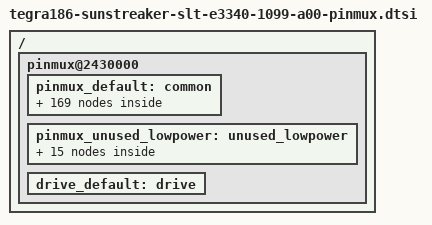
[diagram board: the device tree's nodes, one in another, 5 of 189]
/*
 * Copyright (c) 2015, NVIDIA CORPORATION.  All rights reserved.
 *
 * This program is free software; you can redistribute it and/or modify
 * it under the terms of the GNU General Public License as published by
 * the Free Software Foundation; either version 2 of the License, or
 * (at your option) any later version.
 *
 * This program is distributed in the hope that it will be useful, but WITHOUT
 * ANY WARRANTY; without even the implied warranty of MERCHANTABILITY or
 * FITNESS FOR A PARTICULAR PURPOSE.  See the GNU General Public License for
 * more details.
 */

#include <dt-bindings/pinctrl/pinctrl-tegra.h>

/ {
	pinmux@2430000 {
		pinctrl-names = "default", "drive", "unused";
		pinctrl-0 = <&pinmux_default>;
		pinctrl-1 = <&drive_default>;
		pinctrl-2 = <&pinmux_unused_lowpower>;

		pinmux_default: common {
			/* SFIO Pin Configuration */
			uart4_tx_pb0 {
				nvidia,pins = "uart4_tx_pb0";
				nvidia,function = "uartd";
				nvidia,pull = <TEGRA_PIN_PULL_NONE>;
				nvidia,tristate = <TEGRA_PIN_DISABLE>;
				nvidia,enable-input = <TEGRA_PIN_DISABLE>;
			};

			uart4_rx_pb1 {
				nvidia,pins = "uart4_rx_pb1";
				nvidia,function = "uartd";
				nvidia,pull = <TEGRA_PIN_PULL_UP>;
				nvidia,tristate = <TEGRA_PIN_DISABLE>;
				nvidia,enable-input = <TEGRA_PIN_ENABLE>;
			};

			uart4_rts_pb2 {
				nvidia,pins = "uart4_rts_pb2";
				nvidia,function = "uartd";
				nvidia,pull = <TEGRA_PIN_PULL_NONE>;
				nvidia,tristate = <TEGRA_PIN_DISABLE>;
				nvidia,enable-input = <TEGRA_PIN_DISABLE>;
			};

			uart4_cts_pb3 {
				nvidia,pins = "uart4_cts_pb3";
				nvidia,function = "uartd";
				nvidia,pull = <TEGRA_PIN_PULL_UP>;
				nvidia,tristate = <TEGRA_PIN_DISABLE>;
				nvidia,enable-input = <TEGRA_PIN_ENABLE>;
			};

			dap2_sclk_pc1 {
				nvidia,pins = "dap2_sclk_pc1";
				nvidia,function = "i2s2";
				nvidia,pull = <TEGRA_PIN_PULL_NONE>;
				nvidia,tristate = <TEGRA_PIN_DISABLE>;
				nvidia,enable-input = <TEGRA_PIN_ENABLE>;
			};

			dap2_dout_pc2 {
				nvidia,pins = "dap2_dout_pc2";
				nvidia,function = "i2s2";
				nvidia,pull = <TEGRA_PIN_PULL_NONE>;
				nvidia,tristate = <TEGRA_PIN_DISABLE>;
				nvidia,enable-input = <TEGRA_PIN_ENABLE>;
			};

			dap2_din_pc3 {
				nvidia,pins = "dap2_din_pc3";
				nvidia,function = "i2s2";
				nvidia,pull = <TEGRA_PIN_PULL_NONE>;
				nvidia,tristate = <TEGRA_PIN_DISABLE>;
				nvidia,enable-input = <TEGRA_PIN_ENABLE>;
			};

			dap2_fs_pc4 {
				nvidia,pins = "dap2_fs_pc4";
				nvidia,function = "i2s2";
				nvidia,pull = <TEGRA_PIN_PULL_NONE>;
				nvidia,tristate = <TEGRA_PIN_DISABLE>;
				nvidia,enable-input = <TEGRA_PIN_ENABLE>;
			};

			gen1_i2c_scl_pc5 {
				nvidia,pins = "gen1_i2c_scl_pc5";
				nvidia,function = "i2c1";
				nvidia,pull = <TEGRA_PIN_PULL_NONE>;
				nvidia,tristate = <TEGRA_PIN_DISABLE>;
				nvidia,enable-input = <TEGRA_PIN_ENABLE>;
				nvidia,io-high-voltage = <TEGRA_PIN_DISABLE>;
			};

			gen1_i2c_sda_pc6 {
				nvidia,pins = "gen1_i2c_sda_pc6";
				nvidia,function = "i2c1";
				nvidia,pull = <TEGRA_PIN_PULL_NONE>;
				nvidia,tristate = <TEGRA_PIN_DISABLE>;
				nvidia,enable-input = <TEGRA_PIN_ENABLE>;
				nvidia,io-high-voltage = <TEGRA_PIN_DISABLE>;
			};

			dap1_sclk_pj0 {
				nvidia,pins = "dap1_sclk_pj0";
				nvidia,function = "i2s1";
				nvidia,pull = <TEGRA_PIN_PULL_NONE>;
				nvidia,tristate = <TEGRA_PIN_DISABLE>;
				nvidia,enable-input = <TEGRA_PIN_ENABLE>;
			};

			dap1_dout_pj1 {
				nvidia,pins = "dap1_dout_pj1";
				nvidia,function = "i2s1";
				nvidia,pull = <TEGRA_PIN_PULL_NONE>;
				nvidia,tristate = <TEGRA_PIN_DISABLE>;
				nvidia,enable-input = <TEGRA_PIN_ENABLE>;
			};

			dap1_din_pj2 {
				nvidia,pins = "dap1_din_pj2";
				nvidia,function = "i2s1";
				nvidia,pull = <TEGRA_PIN_PULL_NONE>;
				nvidia,tristate = <TEGRA_PIN_DISABLE>;
				nvidia,enable-input = <TEGRA_PIN_ENABLE>;
			};

			dap1_fs_pj3 {
				nvidia,pins = "dap1_fs_pj3";
				nvidia,function = "i2s1";
				nvidia,pull = <TEGRA_PIN_PULL_NONE>;
				nvidia,tristate = <TEGRA_PIN_DISABLE>;
				nvidia,enable-input = <TEGRA_PIN_ENABLE>;
			};

			aud_mclk_pj4 {
				nvidia,pins = "aud_mclk_pj4";
				nvidia,function = "aud";
				nvidia,pull = <TEGRA_PIN_PULL_NONE>;
				nvidia,tristate = <TEGRA_PIN_DISABLE>;
				nvidia,enable-input = <TEGRA_PIN_DISABLE>;
			};

			dmic1_clk_pm1 {
				nvidia,pins = "dmic1_clk_pm1";
				nvidia,function = "i2s3";
				nvidia,pull = <TEGRA_PIN_PULL_NONE>;
				nvidia,tristate = <TEGRA_PIN_DISABLE>;
				nvidia,enable-input = <TEGRA_PIN_ENABLE>;
			};

			dmic1_dat_pm0 {
				nvidia,pins = "dmic1_dat_pm0";
				nvidia,function = "i2s3";
				nvidia,pull = <TEGRA_PIN_PULL_NONE>;
				nvidia,tristate = <TEGRA_PIN_DISABLE>;
				nvidia,enable-input = <TEGRA_PIN_ENABLE>;
			};

			dmic2_clk_pm3 {
				nvidia,pins = "dmic2_clk_pm3";
				nvidia,function = "i2s3";
				nvidia,pull = <TEGRA_PIN_PULL_NONE>;
				nvidia,tristate = <TEGRA_PIN_DISABLE>;
				nvidia,enable-input = <TEGRA_PIN_ENABLE>;
			};

			dmic2_dat_pm2 {
				nvidia,pins = "dmic2_dat_pm2";
				nvidia,function = "i2s3";
				nvidia,pull = <TEGRA_PIN_PULL_NONE>;
				nvidia,tristate = <TEGRA_PIN_DISABLE>;
				nvidia,enable-input = <TEGRA_PIN_ENABLE>;
			};

			dap4_sclk_pcc0 {
				nvidia,pins = "dap4_sclk_pcc0";
				nvidia,function = "i2s4";
				nvidia,pull = <TEGRA_PIN_PULL_NONE>;
				nvidia,tristate = <TEGRA_PIN_DISABLE>;
				nvidia,enable-input = <TEGRA_PIN_ENABLE>;
			};

			dap4_dout_pcc1 {
				nvidia,pins = "dap4_dout_pcc1";
				nvidia,function = "i2s4";
				nvidia,pull = <TEGRA_PIN_PULL_NONE>;
				nvidia,tristate = <TEGRA_PIN_DISABLE>;
				nvidia,enable-input = <TEGRA_PIN_ENABLE>;
			};

			dap4_din_pcc2 {
				nvidia,pins = "dap4_din_pcc2";
				nvidia,function = "i2s4";
				nvidia,pull = <TEGRA_PIN_PULL_NONE>;
				nvidia,tristate = <TEGRA_PIN_DISABLE>;
				nvidia,enable-input = <TEGRA_PIN_ENABLE>;
			};

			dap4_fs_pcc3 {
				nvidia,pins = "dap4_fs_pcc3";
				nvidia,function = "i2s4";
				nvidia,pull = <TEGRA_PIN_PULL_NONE>;
				nvidia,tristate = <TEGRA_PIN_DISABLE>;
				nvidia,enable-input = <TEGRA_PIN_ENABLE>;
			};

			pq0 {
				nvidia,pins = "pq0";
				nvidia,function = "i2s6";
				nvidia,pull = <TEGRA_PIN_PULL_NONE>;
				nvidia,tristate = <TEGRA_PIN_DISABLE>;
				nvidia,enable-input = <TEGRA_PIN_ENABLE>;
			};

			pq1 {
				nvidia,pins = "pq1";
				nvidia,function = "i2s6";
				nvidia,pull = <TEGRA_PIN_PULL_NONE>;
				nvidia,tristate = <TEGRA_PIN_DISABLE>;
				nvidia,enable-input = <TEGRA_PIN_ENABLE>;
			};

			pq2 {
				nvidia,pins = "pq2";
				nvidia,function = "i2s6";
				nvidia,pull = <TEGRA_PIN_PULL_NONE>;
				nvidia,tristate = <TEGRA_PIN_DISABLE>;
				nvidia,enable-input = <TEGRA_PIN_ENABLE>;
			};

			pq3 {
				nvidia,pins = "pq3";
				nvidia,function = "i2s6";
				nvidia,pull = <TEGRA_PIN_PULL_NONE>;
				nvidia,tristate = <TEGRA_PIN_DISABLE>;
				nvidia,enable-input = <TEGRA_PIN_ENABLE>;
			};

			gpio_cam2_pn1 {
				nvidia,pins = "gpio_cam2_pn1";
				nvidia,function = "extperiph3";
				nvidia,pull = <TEGRA_PIN_PULL_NONE>;
				nvidia,tristate = <TEGRA_PIN_DISABLE>;
				nvidia,enable-input = <TEGRA_PIN_DISABLE>;
			};

			gpio_cam4_pn3 {
				nvidia,pins = "gpio_cam4_pn3";
				nvidia,function = "spi4";
				nvidia,pull = <TEGRA_PIN_PULL_NONE>;
				nvidia,tristate = <TEGRA_PIN_DISABLE>;
				nvidia,enable-input = <TEGRA_PIN_DISABLE>;
			};

			gpio_cam5_pn4 {
				nvidia,pins = "gpio_cam5_pn4";
				nvidia,function = "spi4";
				nvidia,pull = <TEGRA_PIN_PULL_NONE>;
				nvidia,tristate = <TEGRA_PIN_DISABLE>;
				nvidia,enable-input = <TEGRA_PIN_ENABLE>;
			};

			gpio_cam6_pn5 {
				nvidia,pins = "gpio_cam6_pn5";
				nvidia,function = "spi4";
				nvidia,pull = <TEGRA_PIN_PULL_NONE>;
				nvidia,tristate = <TEGRA_PIN_DISABLE>;
				nvidia,enable-input = <TEGRA_PIN_DISABLE>;
			};

			gpio_cam7_pn6 {
				nvidia,pins = "gpio_cam7_pn6";
				nvidia,function = "spi4";
				nvidia,pull = <TEGRA_PIN_PULL_NONE>;
				nvidia,tristate = <TEGRA_PIN_DISABLE>;
				nvidia,enable-input = <TEGRA_PIN_DISABLE>;
			};

			cam_i2c_scl_po2 {
				nvidia,pins = "cam_i2c_scl_po2";
				nvidia,function = "i2c3";
				nvidia,pull = <TEGRA_PIN_PULL_NONE>;
				nvidia,tristate = <TEGRA_PIN_DISABLE>;
				nvidia,enable-input = <TEGRA_PIN_ENABLE>;
				nvidia,io-high-voltage = <TEGRA_PIN_DISABLE>;
			};

			cam_i2c_sda_po3 {
				nvidia,pins = "cam_i2c_sda_po3";
				nvidia,function = "i2c3";
				nvidia,pull = <TEGRA_PIN_PULL_NONE>;
				nvidia,tristate = <TEGRA_PIN_DISABLE>;
				nvidia,enable-input = <TEGRA_PIN_ENABLE>;
				nvidia,io-high-voltage = <TEGRA_PIN_DISABLE>;
			};

			pex_l1_rst_n_pa3 {
				nvidia,pins = "pex_l1_rst_n_pa3";
				nvidia,function = "pe1";
				nvidia,pull = <TEGRA_PIN_PULL_NONE>;
				nvidia,tristate = <TEGRA_PIN_DISABLE>;
				nvidia,enable-input = <TEGRA_PIN_DISABLE>;
				nvidia,io-high-voltage = <TEGRA_PIN_ENABLE>;
			};

			pex_l1_clkreq_n_pa4 {
				nvidia,pins = "pex_l1_clkreq_n_pa4";
				nvidia,function = "pe1";
				nvidia,pull = <TEGRA_PIN_PULL_NONE>;
				nvidia,tristate = <TEGRA_PIN_DISABLE>;
				nvidia,enable-input = <TEGRA_PIN_ENABLE>;
				nvidia,io-high-voltage = <TEGRA_PIN_ENABLE>;
			};

			pex_wake_n_pa2 {
				nvidia,pins = "pex_wake_n_pa2";
				nvidia,function = "pe";
				nvidia,pull = <TEGRA_PIN_PULL_NONE>;
				nvidia,tristate = <TEGRA_PIN_DISABLE>;
				nvidia,enable-input = <TEGRA_PIN_ENABLE>;
				nvidia,io-high-voltage = <TEGRA_PIN_ENABLE>;
			};

			sdmmc1_clk_pd0 {
				nvidia,pins = "sdmmc1_clk_pd0";
				nvidia,function = "sdmmc1";
				nvidia,pull = <TEGRA_PIN_PULL_NONE>;
				nvidia,tristate = <TEGRA_PIN_DISABLE>;
				nvidia,enable-input = <TEGRA_PIN_ENABLE>;
			};

			sdmmc1_cmd_pd1 {
				nvidia,pins = "sdmmc1_cmd_pd1";
				nvidia,function = "sdmmc1";
				nvidia,pull = <TEGRA_PIN_PULL_UP>;
				nvidia,tristate = <TEGRA_PIN_DISABLE>;
				nvidia,enable-input = <TEGRA_PIN_ENABLE>;
			};

			sdmmc1_dat0_pd2 {
				nvidia,pins = "sdmmc1_dat0_pd2";
				nvidia,function = "sdmmc1";
				nvidia,pull = <TEGRA_PIN_PULL_UP>;
				nvidia,tristate = <TEGRA_PIN_DISABLE>;
				nvidia,enable-input = <TEGRA_PIN_ENABLE>;
			};

			sdmmc1_dat1_pd3 {
				nvidia,pins = "sdmmc1_dat1_pd3";
				nvidia,function = "sdmmc1";
				nvidia,pull = <TEGRA_PIN_PULL_UP>;
				nvidia,tristate = <TEGRA_PIN_DISABLE>;
				nvidia,enable-input = <TEGRA_PIN_ENABLE>;
			};

			sdmmc1_dat2_pd4 {
				nvidia,pins = "sdmmc1_dat2_pd4";
				nvidia,function = "sdmmc1";
				nvidia,pull = <TEGRA_PIN_PULL_UP>;
				nvidia,tristate = <TEGRA_PIN_DISABLE>;
				nvidia,enable-input = <TEGRA_PIN_ENABLE>;
			};

			sdmmc1_dat3_pd5 {
				nvidia,pins = "sdmmc1_dat3_pd5";
				nvidia,function = "sdmmc1";
				nvidia,pull = <TEGRA_PIN_PULL_UP>;
				nvidia,tristate = <TEGRA_PIN_DISABLE>;
				nvidia,enable-input = <TEGRA_PIN_ENABLE>;
			};

			eqos_txc_pe0 {
				nvidia,pins = "eqos_txc_pe0";
				nvidia,function = "eqos";
				nvidia,pull = <TEGRA_PIN_PULL_NONE>;
				nvidia,tristate = <TEGRA_PIN_DISABLE>;
				nvidia,enable-input = <TEGRA_PIN_DISABLE>;
			};

			eqos_td0_pe1 {
				nvidia,pins = "eqos_td0_pe1";
				nvidia,function = "eqos";
				nvidia,pull = <TEGRA_PIN_PULL_NONE>;
				nvidia,tristate = <TEGRA_PIN_DISABLE>;
				nvidia,enable-input = <TEGRA_PIN_DISABLE>;
			};

			eqos_td1_pe2 {
				nvidia,pins = "eqos_td1_pe2";
				nvidia,function = "eqos";
				nvidia,pull = <TEGRA_PIN_PULL_NONE>;
				nvidia,tristate = <TEGRA_PIN_DISABLE>;
				nvidia,enable-input = <TEGRA_PIN_DISABLE>;
			};

			eqos_td2_pe3 {
				nvidia,pins = "eqos_td2_pe3";
				nvidia,function = "eqos";
				nvidia,pull = <TEGRA_PIN_PULL_NONE>;
				nvidia,tristate = <TEGRA_PIN_DISABLE>;
				nvidia,enable-input = <TEGRA_PIN_DISABLE>;
			};

			eqos_td3_pe4 {
				nvidia,pins = "eqos_td3_pe4";
				nvidia,function = "eqos";
				nvidia,pull = <TEGRA_PIN_PULL_NONE>;
				nvidia,tristate = <TEGRA_PIN_DISABLE>;
				nvidia,enable-input = <TEGRA_PIN_DISABLE>;
			};

			eqos_tx_ctl_pe5 {
				nvidia,pins = "eqos_tx_ctl_pe5";
				nvidia,function = "eqos";
				nvidia,pull = <TEGRA_PIN_PULL_NONE>;
				nvidia,tristate = <TEGRA_PIN_DISABLE>;
				nvidia,enable-input = <TEGRA_PIN_DISABLE>;
			};

			eqos_rd0_pe6 {
				nvidia,pins = "eqos_rd0_pe6";
				nvidia,function = "eqos";
				nvidia,pull = <TEGRA_PIN_PULL_NONE>;
				nvidia,tristate = <TEGRA_PIN_DISABLE>;
				nvidia,enable-input = <TEGRA_PIN_ENABLE>;
			};

			eqos_rd1_pe7 {
				nvidia,pins = "eqos_rd1_pe7";
				nvidia,function = "eqos";
				nvidia,pull = <TEGRA_PIN_PULL_NONE>;
				nvidia,tristate = <TEGRA_PIN_DISABLE>;
				nvidia,enable-input = <TEGRA_PIN_ENABLE>;
			};

			eqos_rd2_pf0 {
				nvidia,pins = "eqos_rd2_pf0";
				nvidia,function = "eqos";
				nvidia,pull = <TEGRA_PIN_PULL_NONE>;
				nvidia,tristate = <TEGRA_PIN_DISABLE>;
				nvidia,enable-input = <TEGRA_PIN_ENABLE>;
			};

			eqos_rd3_pf1 {
				nvidia,pins = "eqos_rd3_pf1";
				nvidia,function = "eqos";
				nvidia,pull = <TEGRA_PIN_PULL_NONE>;
				nvidia,tristate = <TEGRA_PIN_DISABLE>;
				nvidia,enable-input = <TEGRA_PIN_ENABLE>;
			};

			eqos_rx_ctl_pf2 {
				nvidia,pins = "eqos_rx_ctl_pf2";
				nvidia,function = "eqos";
				nvidia,pull = <TEGRA_PIN_PULL_NONE>;
				nvidia,tristate = <TEGRA_PIN_DISABLE>;
				nvidia,enable-input = <TEGRA_PIN_ENABLE>;
			};

			eqos_rxc_pf3 {
				nvidia,pins = "eqos_rxc_pf3";
				nvidia,function = "eqos";
				nvidia,pull = <TEGRA_PIN_PULL_NONE>;
				nvidia,tristate = <TEGRA_PIN_DISABLE>;
				nvidia,enable-input = <TEGRA_PIN_ENABLE>;
			};

			eqos_mdio_pf4 {
				nvidia,pins = "eqos_mdio_pf4";
				nvidia,function = "eqos";
				nvidia,pull = <TEGRA_PIN_PULL_NONE>;
				nvidia,tristate = <TEGRA_PIN_DISABLE>;
				nvidia,enable-input = <TEGRA_PIN_ENABLE>;
			};

			eqos_mdc_pf5 {
				nvidia,pins = "eqos_mdc_pf5";
				nvidia,function = "eqos";
				nvidia,pull = <TEGRA_PIN_PULL_NONE>;
				nvidia,tristate = <TEGRA_PIN_DISABLE>;
				nvidia,enable-input = <TEGRA_PIN_DISABLE>;
			};

			sdmmc3_clk_pg0 {
				nvidia,pins = "sdmmc3_clk_pg0";
				nvidia,function = "sdmmc3";
				nvidia,pull = <TEGRA_PIN_PULL_NONE>;
				nvidia,tristate = <TEGRA_PIN_DISABLE>;
				nvidia,enable-input = <TEGRA_PIN_ENABLE>;
			};

			sdmmc3_cmd_pg1 {
				nvidia,pins = "sdmmc3_cmd_pg1";
				nvidia,function = "sdmmc3";
				nvidia,pull = <TEGRA_PIN_PULL_UP>;
				nvidia,tristate = <TEGRA_PIN_DISABLE>;
				nvidia,enable-input = <TEGRA_PIN_ENABLE>;
			};

			sdmmc3_dat0_pg2 {
				nvidia,pins = "sdmmc3_dat0_pg2";
				nvidia,function = "sdmmc3";
				nvidia,pull = <TEGRA_PIN_PULL_UP>;
				nvidia,tristate = <TEGRA_PIN_DISABLE>;
				nvidia,enable-input = <TEGRA_PIN_ENABLE>;
			};

			sdmmc3_dat1_pg3 {
				nvidia,pins = "sdmmc3_dat1_pg3";
				nvidia,function = "sdmmc3";
				nvidia,pull = <TEGRA_PIN_PULL_UP>;
				nvidia,tristate = <TEGRA_PIN_DISABLE>;
				nvidia,enable-input = <TEGRA_PIN_ENABLE>;
			};

			sdmmc3_dat2_pg4 {
				nvidia,pins = "sdmmc3_dat2_pg4";
				nvidia,function = "sdmmc3";
				nvidia,pull = <TEGRA_PIN_PULL_UP>;
				nvidia,tristate = <TEGRA_PIN_DISABLE>;
				nvidia,enable-input = <TEGRA_PIN_ENABLE>;
			};

			sdmmc3_dat3_pg5 {
				nvidia,pins = "sdmmc3_dat3_pg5";
				nvidia,function = "sdmmc3";
				nvidia,pull = <TEGRA_PIN_PULL_UP>;
				nvidia,tristate = <TEGRA_PIN_DISABLE>;
				nvidia,enable-input = <TEGRA_PIN_ENABLE>;
			};

			safe_state_ps3 {
				nvidia,pins = "safe_state_ps3";
				nvidia,function = "sce";
				nvidia,pull = <TEGRA_PIN_PULL_NONE>;
				nvidia,tristate = <TEGRA_PIN_DISABLE>;
				nvidia,enable-input = <TEGRA_PIN_DISABLE>;
			};

			pwr_i2c_scl_ps0 {
				nvidia,pins = "pwr_i2c_scl_ps0";
				nvidia,function = "i2c5";
				nvidia,pull = <TEGRA_PIN_PULL_NONE>;
				nvidia,tristate = <TEGRA_PIN_DISABLE>;
				nvidia,enable-input = <TEGRA_PIN_ENABLE>;
				nvidia,io-high-voltage = <TEGRA_PIN_DISABLE>;
			};

			pwr_i2c_sda_ps1 {
				nvidia,pins = "pwr_i2c_sda_ps1";
				nvidia,function = "i2c5";
				nvidia,pull = <TEGRA_PIN_PULL_NONE>;
				nvidia,tristate = <TEGRA_PIN_DISABLE>;
				nvidia,enable-input = <TEGRA_PIN_ENABLE>;
				nvidia,io-high-voltage = <TEGRA_PIN_DISABLE>;
			};

			uart2_tx_px0 {
				nvidia,pins = "uart2_tx_px0";
				nvidia,function = "uartb";
				nvidia,pull = <TEGRA_PIN_PULL_NONE>;
				nvidia,tristate = <TEGRA_PIN_DISABLE>;
				nvidia,enable-input = <TEGRA_PIN_DISABLE>;
			};

			uart2_rx_px1 {
				nvidia,pins = "uart2_rx_px1";
				nvidia,function = "uartb";
				nvidia,pull = <TEGRA_PIN_PULL_UP>;
				nvidia,tristate = <TEGRA_PIN_DISABLE>;
				nvidia,enable-input = <TEGRA_PIN_ENABLE>;
			};

			uart5_tx_px4 {
				nvidia,pins = "uart5_tx_px4";
				nvidia,function = "spi3";
				nvidia,pull = <TEGRA_PIN_PULL_NONE>;
				nvidia,tristate = <TEGRA_PIN_DISABLE>;
				nvidia,enable-input = <TEGRA_PIN_DISABLE>;
			};

			uart5_rx_px5 {
				nvidia,pins = "uart5_rx_px5";
				nvidia,function = "spi3";
				nvidia,pull = <TEGRA_PIN_PULL_NONE>;
				nvidia,tristate = <TEGRA_PIN_DISABLE>;
				nvidia,enable-input = <TEGRA_PIN_ENABLE>;
			};

			uart5_rts_px6 {
				nvidia,pins = "uart5_rts_px6";
				nvidia,function = "spi3";
				nvidia,pull = <TEGRA_PIN_PULL_NONE>;
				nvidia,tristate = <TEGRA_PIN_DISABLE>;
				nvidia,enable-input = <TEGRA_PIN_DISABLE>;
			};

			uart5_cts_px7 {
				nvidia,pins = "uart5_cts_px7";
				nvidia,function = "spi3";
				nvidia,pull = <TEGRA_PIN_PULL_NONE>;
				nvidia,tristate = <TEGRA_PIN_DISABLE>;
				nvidia,enable-input = <TEGRA_PIN_DISABLE>;
			};

			gpio_mdm4_py3 {
				nvidia,pins = "gpio_mdm4_py3";
				nvidia,function = "spi1";
				nvidia,pull = <TEGRA_PIN_PULL_NONE>;
				nvidia,tristate = <TEGRA_PIN_DISABLE>;
				nvidia,enable-input = <TEGRA_PIN_DISABLE>;
			};

			gen7_i2c_scl_pl0 {
				nvidia,pins = "gen7_i2c_scl_pl0";
				nvidia,function = "i2s5";
				nvidia,pull = <TEGRA_PIN_PULL_NONE>;
				nvidia,tristate = <TEGRA_PIN_DISABLE>;
				nvidia,enable-input = <TEGRA_PIN_ENABLE>;
				nvidia,io-high-voltage = <TEGRA_PIN_DISABLE>;
			};

			gen7_i2c_sda_pl1 {
				nvidia,pins = "gen7_i2c_sda_pl1";
				nvidia,function = "i2s5";
				nvidia,pull = <TEGRA_PIN_PULL_NONE>;
				nvidia,tristate = <TEGRA_PIN_DISABLE>;
				nvidia,enable-input = <TEGRA_PIN_ENABLE>;
				nvidia,io-high-voltage = <TEGRA_PIN_DISABLE>;
			};

			gen9_i2c_scl_pl2 {
				nvidia,pins = "gen9_i2c_scl_pl2";
				nvidia,function = "i2s5";
				nvidia,pull = <TEGRA_PIN_PULL_NONE>;
				nvidia,tristate = <TEGRA_PIN_DISABLE>;
				nvidia,enable-input = <TEGRA_PIN_ENABLE>;
				nvidia,io-high-voltage = <TEGRA_PIN_DISABLE>;
			};

			gen9_i2c_sda_pl3 {
				nvidia,pins = "gen9_i2c_sda_pl3";
				nvidia,function = "i2s5";
				nvidia,pull = <TEGRA_PIN_PULL_NONE>;
				nvidia,tristate = <TEGRA_PIN_DISABLE>;
				nvidia,enable-input = <TEGRA_PIN_ENABLE>;
				nvidia,io-high-voltage = <TEGRA_PIN_DISABLE>;
			};

			gpio_wan5_ph0 {
				nvidia,pins = "gpio_wan5_ph0";
				nvidia,function = "spi1";
				nvidia,pull = <TEGRA_PIN_PULL_NONE>;
				nvidia,tristate = <TEGRA_PIN_DISABLE>;
				nvidia,enable-input = <TEGRA_PIN_DISABLE>;
			};

			gpio_wan6_ph1 {
				nvidia,pins = "gpio_wan6_ph1";
				nvidia,function = "spi1";
				nvidia,pull = <TEGRA_PIN_PULL_NONE>;
				nvidia,tristate = <TEGRA_PIN_DISABLE>;
				nvidia,enable-input = <TEGRA_PIN_ENABLE>;
			};

			gpio_wan7_ph2 {
				nvidia,pins = "gpio_wan7_ph2";
				nvidia,function = "spi1";
				nvidia,pull = <TEGRA_PIN_PULL_NONE>;
				nvidia,tristate = <TEGRA_PIN_DISABLE>;
				nvidia,enable-input = <TEGRA_PIN_DISABLE>;
			};

			gpio_wan8_ph3 {
				nvidia,pins = "gpio_wan8_ph3";
				nvidia,function = "spi1";
				nvidia,pull = <TEGRA_PIN_PULL_NONE>;
				nvidia,tristate = <TEGRA_PIN_DISABLE>;
				nvidia,enable-input = <TEGRA_PIN_DISABLE>;
			};

			uart1_tx_pt0 {
				nvidia,pins = "uart1_tx_pt0";
				nvidia,function = "uarta";
				nvidia,pull = <TEGRA_PIN_PULL_NONE>;
				nvidia,tristate = <TEGRA_PIN_DISABLE>;
				nvidia,enable-input = <TEGRA_PIN_DISABLE>;
			};

			uart1_rx_pt1 {
				nvidia,pins = "uart1_rx_pt1";
				nvidia,function = "uarta";
				nvidia,pull = <TEGRA_PIN_PULL_UP>;
				nvidia,tristate = <TEGRA_PIN_DISABLE>;
				nvidia,enable-input = <TEGRA_PIN_ENABLE>;
			};

			uart1_rts_pt2 {
				nvidia,pins = "uart1_rts_pt2";
				nvidia,function = "uarta";
				nvidia,pull = <TEGRA_PIN_PULL_NONE>;
				nvidia,tristate = <TEGRA_PIN_DISABLE>;
				nvidia,enable-input = <TEGRA_PIN_DISABLE>;
			};

			uart1_cts_pt3 {
				nvidia,pins = "uart1_cts_pt3";
				nvidia,function = "uarta";
				nvidia,pull = <TEGRA_PIN_PULL_UP>;
				nvidia,tristate = <TEGRA_PIN_DISABLE>;
				nvidia,enable-input = <TEGRA_PIN_ENABLE>;
			};

			uart3_tx_pw2 {
				nvidia,pins = "uart3_tx_pw2";
				nvidia,function = "uartc";
				nvidia,pull = <TEGRA_PIN_PULL_NONE>;
				nvidia,tristate = <TEGRA_PIN_DISABLE>;
				nvidia,enable-input = <TEGRA_PIN_DISABLE>;
			};

			uart3_rx_pw3 {
				nvidia,pins = "uart3_rx_pw3";
				nvidia,function = "uartc";
				nvidia,pull = <TEGRA_PIN_PULL_NONE>;
				nvidia,tristate = <TEGRA_PIN_DISABLE>;
				nvidia,enable-input = <TEGRA_PIN_ENABLE>;
			};

			gen8_i2c_scl_pw0 {
				nvidia,pins = "gen8_i2c_scl_pw0";
				nvidia,function = "i2c8";
				nvidia,pull = <TEGRA_PIN_PULL_NONE>;
				nvidia,tristate = <TEGRA_PIN_DISABLE>;
				nvidia,enable-input = <TEGRA_PIN_ENABLE>;
				nvidia,io-high-voltage = <TEGRA_PIN_DISABLE>;
			};

			gen8_i2c_sda_pw1 {
				nvidia,pins = "gen8_i2c_sda_pw1";
				nvidia,function = "i2c8";
				nvidia,pull = <TEGRA_PIN_PULL_NONE>;
				nvidia,tristate = <TEGRA_PIN_DISABLE>;
				nvidia,enable-input = <TEGRA_PIN_ENABLE>;
				nvidia,io-high-voltage = <TEGRA_PIN_DISABLE>;
			};

			uart7_tx_pw6 {
				nvidia,pins = "uart7_tx_pw6";
				nvidia,function = "uartg";
				nvidia,pull = <TEGRA_PIN_PULL_NONE>;
				nvidia,tristate = <TEGRA_PIN_DISABLE>;
				nvidia,enable-input = <TEGRA_PIN_DISABLE>;
			};

			uart7_rx_pw7 {
				nvidia,pins = "uart7_rx_pw7";
				nvidia,function = "uartg";
				nvidia,pull = <TEGRA_PIN_PULL_NONE>;
				nvidia,tristate = <TEGRA_PIN_DISABLE>;
				nvidia,enable-input = <TEGRA_PIN_ENABLE>;
			};

			gpio_sen1_pv1 {
				nvidia,pins = "gpio_sen1_pv1";
				nvidia,function = "spi2";
				nvidia,pull = <TEGRA_PIN_PULL_NONE>;
				nvidia,tristate = <TEGRA_PIN_DISABLE>;
				nvidia,enable-input = <TEGRA_PIN_DISABLE>;
			};

			gpio_sen2_pv2 {
				nvidia,pins = "gpio_sen2_pv2";
				nvidia,function = "spi2";
				nvidia,pull = <TEGRA_PIN_PULL_NONE>;
				nvidia,tristate = <TEGRA_PIN_DISABLE>;
				nvidia,enable-input = <TEGRA_PIN_ENABLE>;
			};

			gpio_sen3_pv3 {
				nvidia,pins = "gpio_sen3_pv3";
				nvidia,function = "spi2";
				nvidia,pull = <TEGRA_PIN_PULL_NONE>;
				nvidia,tristate = <TEGRA_PIN_DISABLE>;
				nvidia,enable-input = <TEGRA_PIN_DISABLE>;
			};

			gpio_sen4_pv4 {
				nvidia,pins = "gpio_sen4_pv4";
				nvidia,function = "spi2";
				nvidia,pull = <TEGRA_PIN_PULL_NONE>;
				nvidia,tristate = <TEGRA_PIN_DISABLE>;
				nvidia,enable-input = <TEGRA_PIN_DISABLE>;
			};

			gpio_sen6_pv6 {
				nvidia,pins = "gpio_sen6_pv6";
				nvidia,function = "gp";
				nvidia,pull = <TEGRA_PIN_PULL_NONE>;
				nvidia,tristate = <TEGRA_PIN_DISABLE>;
				nvidia,enable-input = <TEGRA_PIN_DISABLE>;
			};

			gpio_sen8_pee0 {
				nvidia,pins = "gpio_sen8_pee0";
				nvidia,function = "i2c2";
				nvidia,pull = <TEGRA_PIN_PULL_NONE>;
				nvidia,tristate = <TEGRA_PIN_DISABLE>;
				nvidia,enable-input = <TEGRA_PIN_ENABLE>;
				nvidia,io-high-voltage = <TEGRA_PIN_DISABLE>;
			};

			gpio_sen9_pee1 {
				nvidia,pins = "gpio_sen9_pee1";
				nvidia,function = "i2c2";
				nvidia,pull = <TEGRA_PIN_PULL_NONE>;
				nvidia,tristate = <TEGRA_PIN_DISABLE>;
				nvidia,enable-input = <TEGRA_PIN_ENABLE>;
				nvidia,io-high-voltage = <TEGRA_PIN_DISABLE>;
			};

			can1_dout_pz0 {
				nvidia,pins = "can1_dout_pz0";
				nvidia,function = "can1";
				nvidia,pull = <TEGRA_PIN_PULL_NONE>;
				nvidia,tristate = <TEGRA_PIN_DISABLE>;
				nvidia,enable-input = <TEGRA_PIN_DISABLE>;
			};

			can1_din_pz1 {
				nvidia,pins = "can1_din_pz1";
				nvidia,function = "can1";
				nvidia,pull = <TEGRA_PIN_PULL_NONE>;
				nvidia,tristate = <TEGRA_PIN_DISABLE>;
				nvidia,enable-input = <TEGRA_PIN_ENABLE>;
			};

			can0_dout_pz2 {
				nvidia,pins = "can0_dout_pz2";
				nvidia,function = "can0";
				nvidia,pull = <TEGRA_PIN_PULL_NONE>;
				nvidia,tristate = <TEGRA_PIN_DISABLE>;
				nvidia,enable-input = <TEGRA_PIN_DISABLE>;
			};

			can0_din_pz3 {
				nvidia,pins = "can0_din_pz3";
				nvidia,function = "can0";
				nvidia,pull = <TEGRA_PIN_PULL_NONE>;
				nvidia,tristate = <TEGRA_PIN_DISABLE>;
				nvidia,enable-input = <TEGRA_PIN_ENABLE>;
			};

			qspi_io0_pr1 {
				nvidia,pins = "qspi_io0_pr1";
				nvidia,function = "qspi";
				nvidia,pull = <TEGRA_PIN_PULL_NONE>;
				nvidia,tristate = <TEGRA_PIN_DISABLE>;
				nvidia,enable-input = <TEGRA_PIN_ENABLE>;
			};

			qspi_io1_pr2 {
				nvidia,pins = "qspi_io1_pr2";
				nvidia,function = "qspi";
				nvidia,pull = <TEGRA_PIN_PULL_NONE>;
				nvidia,tristate = <TEGRA_PIN_DISABLE>;
				nvidia,enable-input = <TEGRA_PIN_ENABLE>;
			};

			qspi_sck_pr0 {
				nvidia,pins = "qspi_sck_pr0";
				nvidia,function = "qspi";
				nvidia,pull = <TEGRA_PIN_PULL_NONE>;
				nvidia,tristate = <TEGRA_PIN_DISABLE>;
				nvidia,enable-input = <TEGRA_PIN_ENABLE>;
			};

			qspi_cs_n_pr5 {
				nvidia,pins = "qspi_cs_n_pr5";
				nvidia,function = "qspi";
				nvidia,pull = <TEGRA_PIN_PULL_NONE>;
				nvidia,tristate = <TEGRA_PIN_DISABLE>;
				nvidia,enable-input = <TEGRA_PIN_DISABLE>;
			};

			qspi_io2_pr3 {
				nvidia,pins = "qspi_io2_pr3";
				nvidia,function = "qspi";
				nvidia,pull = <TEGRA_PIN_PULL_NONE>;
				nvidia,tristate = <TEGRA_PIN_DISABLE>;
				nvidia,enable-input = <TEGRA_PIN_ENABLE>;
			};

			qspi_io3_pr4 {
				nvidia,pins = "qspi_io3_pr4";
				nvidia,function = "qspi";
				nvidia,pull = <TEGRA_PIN_PULL_NONE>;
				nvidia,tristate = <TEGRA_PIN_DISABLE>;
				nvidia,enable-input = <TEGRA_PIN_ENABLE>;
			};

			dp_aux_ch0_hpd_pp0 {
				nvidia,pins = "dp_aux_ch0_hpd_pp0";
				nvidia,function = "dp";
				nvidia,pull = <TEGRA_PIN_PULL_NONE>;
				nvidia,tristate = <TEGRA_PIN_DISABLE>;
				nvidia,enable-input = <TEGRA_PIN_ENABLE>;
				nvidia,io-high-voltage = <TEGRA_PIN_DISABLE>;
			};

			hdmi_cec_pp2 {
				nvidia,pins = "hdmi_cec_pp2";
				nvidia,function = "hdmi";
				nvidia,pull = <TEGRA_PIN_PULL_NONE>;
				nvidia,tristate = <TEGRA_PIN_DISABLE>;
				nvidia,enable-input = <TEGRA_PIN_ENABLE>;
				nvidia,io-high-voltage = <TEGRA_PIN_ENABLE>;
			};

			dp_aux_ch1_hpd_pp1 {
				nvidia,pins = "dp_aux_ch1_hpd_pp1";
				nvidia,function = "dp";
				nvidia,pull = <TEGRA_PIN_PULL_NONE>;
				nvidia,tristate = <TEGRA_PIN_DISABLE>;
				nvidia,enable-input = <TEGRA_PIN_ENABLE>;
				nvidia,io-high-voltage = <TEGRA_PIN_DISABLE>;
			};

			/* GPIO Pin Configuration */
			gpio_wan1_pb4 {
				nvidia,pins = "gpio_wan1_pb4";
				nvidia,function = "rsvd0";
				nvidia,pull = <TEGRA_PIN_PULL_NONE>;
				nvidia,tristate = <TEGRA_PIN_DISABLE>;
				nvidia,enable-input = <TEGRA_PIN_DISABLE>;
			};

			gpio_wan2_pb5 {
				nvidia,pins = "gpio_wan2_pb5";
				nvidia,function = "rsvd0";
				nvidia,pull = <TEGRA_PIN_PULL_UP>;
				nvidia,tristate = <TEGRA_PIN_DISABLE>;
				nvidia,enable-input = <TEGRA_PIN_ENABLE>;
			};

			gpio_wan3_pb6 {
				nvidia,pins = "gpio_wan3_pb6";
				nvidia,function = "rsvd0";
				nvidia,pull = <TEGRA_PIN_PULL_NONE>;
				nvidia,tristate = <TEGRA_PIN_DISABLE>;
				nvidia,enable-input = <TEGRA_PIN_DISABLE>;
			};

			gpio_wan4_pc0 {
				nvidia,pins = "gpio_wan4_pc0";
				nvidia,function = "rsvd0";
				nvidia,pull = <TEGRA_PIN_PULL_UP>;
				nvidia,tristate = <TEGRA_PIN_DISABLE>;
				nvidia,enable-input = <TEGRA_PIN_ENABLE>;
			};

			gpio_aud0_pj5 {
				nvidia,pins = "gpio_aud0_pj5";
				nvidia,function = "rsvd0";
				nvidia,pull = <TEGRA_PIN_PULL_NONE>;
				nvidia,tristate = <TEGRA_PIN_DISABLE>;
				nvidia,enable-input = <TEGRA_PIN_DISABLE>;
			};

			gpio_aud1_pj6 {
				nvidia,pins = "gpio_aud1_pj6";
				nvidia,function = "rsvd0";
				nvidia,pull = <TEGRA_PIN_PULL_NONE>;
				nvidia,tristate = <TEGRA_PIN_DISABLE>;
				nvidia,enable-input = <TEGRA_PIN_DISABLE>;
			};

			gpio_aud2_pj7 {
				nvidia,pins = "gpio_aud2_pj7";
				nvidia,function = "rsvd0";
				nvidia,pull = <TEGRA_PIN_PULL_NONE>;
				nvidia,tristate = <TEGRA_PIN_DISABLE>;
				nvidia,enable-input = <TEGRA_PIN_DISABLE>;
			};

			gpio_aud3_pk0 {
				nvidia,pins = "gpio_aud3_pk0";
				nvidia,function = "rsvd0";
				nvidia,pull = <TEGRA_PIN_PULL_NONE>;
				nvidia,tristate = <TEGRA_PIN_DISABLE>;
				nvidia,enable-input = <TEGRA_PIN_DISABLE>;
			};

			dmic4_clk_pm5 {
				nvidia,pins = "dmic4_clk_pm5";
				nvidia,function = "rsvd2";
				nvidia,pull = <TEGRA_PIN_PULL_UP>;
				nvidia,tristate = <TEGRA_PIN_DISABLE>;
				nvidia,enable-input = <TEGRA_PIN_ENABLE>;
			};

			dmic4_dat_pm4 {
				nvidia,pins = "dmic4_dat_pm4";
				nvidia,function = "rsvd2";
				nvidia,pull = <TEGRA_PIN_PULL_NONE>;
				nvidia,tristate = <TEGRA_PIN_DISABLE>;
				nvidia,enable-input = <TEGRA_PIN_DISABLE>;
			};

			pq4 {
				nvidia,pins = "pq4";
				nvidia,function = "rsvd0";
				nvidia,pull = <TEGRA_PIN_PULL_UP>;
				nvidia,tristate = <TEGRA_PIN_DISABLE>;
				nvidia,enable-input = <TEGRA_PIN_ENABLE>;
			};

			pq5 {
				nvidia,pins = "pq5";
				nvidia,function = "rsvd0";
				nvidia,pull = <TEGRA_PIN_PULL_NONE>;
				nvidia,tristate = <TEGRA_PIN_DISABLE>;
				nvidia,enable-input = <TEGRA_PIN_DISABLE>;
			};

			pq6 {
				nvidia,pins = "pq6";
				nvidia,function = "rsvd0";
				nvidia,pull = <TEGRA_PIN_PULL_UP>;
				nvidia,tristate = <TEGRA_PIN_DISABLE>;
				nvidia,enable-input = <TEGRA_PIN_ENABLE>;
			};

			pq7 {
				nvidia,pins = "pq7";
				nvidia,function = "rsvd0";
				nvidia,pull = <TEGRA_PIN_PULL_DOWN>;
				nvidia,tristate = <TEGRA_PIN_DISABLE>;
				nvidia,enable-input = <TEGRA_PIN_ENABLE>;
			};

			extperiph1_clk_po0 {
				nvidia,pins = "extperiph1_clk_po0";
				nvidia,function = "rsvd1";
				nvidia,pull = <TEGRA_PIN_PULL_NONE>;
				nvidia,tristate = <TEGRA_PIN_DISABLE>;
				nvidia,enable-input = <TEGRA_PIN_DISABLE>;
			};

			extperiph2_clk_po1 {
				nvidia,pins = "extperiph2_clk_po1";
				nvidia,function = "rsvd1";
				nvidia,pull = <TEGRA_PIN_PULL_NONE>;
				nvidia,tristate = <TEGRA_PIN_DISABLE>;
				nvidia,enable-input = <TEGRA_PIN_DISABLE>;
			};

			gpio_cam1_pn0 {
				nvidia,pins = "gpio_cam1_pn0";
				nvidia,function = "rsvd1";
				nvidia,pull = <TEGRA_PIN_PULL_UP>;
				nvidia,tristate = <TEGRA_PIN_DISABLE>;
				nvidia,enable-input = <TEGRA_PIN_ENABLE>;
			};

			gpio_cam3_pn2 {
				nvidia,pins = "gpio_cam3_pn2";
				nvidia,function = "rsvd2";
				nvidia,pull = <TEGRA_PIN_PULL_NONE>;
				nvidia,tristate = <TEGRA_PIN_DISABLE>;
				nvidia,enable-input = <TEGRA_PIN_DISABLE>;
			};

			pex_l0_rst_n_pa0 {
				nvidia,pins = "pex_l0_rst_n_pa0";
				nvidia,function = "rsvd1";
				nvidia,pull = <TEGRA_PIN_PULL_NONE>;
				nvidia,tristate = <TEGRA_PIN_DISABLE>;
				nvidia,enable-input = <TEGRA_PIN_DISABLE>;
				nvidia,io-high-voltage = <TEGRA_PIN_DISABLE>;
			};

			pex_l0_clkreq_n_pa1 {
				nvidia,pins = "pex_l0_clkreq_n_pa1";
				nvidia,function = "rsvd1";
				nvidia,pull = <TEGRA_PIN_PULL_NONE>;
				nvidia,tristate = <TEGRA_PIN_DISABLE>;
				nvidia,enable-input = <TEGRA_PIN_ENABLE>;
				nvidia,io-high-voltage = <TEGRA_PIN_DISABLE>;
			};

			pex_l2_rst_n_pa5 {
				nvidia,pins = "pex_l2_rst_n_pa5";
				nvidia,function = "rsvd3";
				nvidia,pull = <TEGRA_PIN_PULL_NONE>;
				nvidia,tristate = <TEGRA_PIN_DISABLE>;
				nvidia,enable-input = <TEGRA_PIN_DISABLE>;
				nvidia,io-high-voltage = <TEGRA_PIN_DISABLE>;
			};

			pex_l2_clkreq_n_pa6 {
				nvidia,pins = "pex_l2_clkreq_n_pa6";
				nvidia,function = "rsvd3";
				nvidia,pull = <TEGRA_PIN_PULL_UP>;
				nvidia,tristate = <TEGRA_PIN_DISABLE>;
				nvidia,enable-input = <TEGRA_PIN_ENABLE>;
				nvidia,io-high-voltage = <TEGRA_PIN_DISABLE>;
			};

			gpio_sw1_pff1 {
				nvidia,pins = "gpio_sw1_pff1";
				nvidia,function = "rsvd0";
				nvidia,pull = <TEGRA_PIN_PULL_UP>;
				nvidia,tristate = <TEGRA_PIN_DISABLE>;
				nvidia,enable-input = <TEGRA_PIN_ENABLE>;
			};

			gpio_sw2_pff2 {
				nvidia,pins = "gpio_sw2_pff2";
				nvidia,function = "rsvd0";
				nvidia,pull = <TEGRA_PIN_PULL_UP>;
				nvidia,tristate = <TEGRA_PIN_DISABLE>;
				nvidia,enable-input = <TEGRA_PIN_ENABLE>;
			};

			gpio_sw4_pff4 {
				nvidia,pins = "gpio_sw4_pff4";
				nvidia,function = "rsvd0";
				nvidia,pull = <TEGRA_PIN_PULL_UP>;
				nvidia,tristate = <TEGRA_PIN_DISABLE>;
				nvidia,enable-input = <TEGRA_PIN_ENABLE>;
			};

			gpio_dis0_pu0 {
				nvidia,pins = "gpio_dis0_pu0";
				nvidia,function = "rsvd0";
				nvidia,pull = <TEGRA_PIN_PULL_NONE>;
				nvidia,tristate = <TEGRA_PIN_DISABLE>;
				nvidia,enable-input = <TEGRA_PIN_DISABLE>;
			};

			gpio_dis1_pu1 {
				nvidia,pins = "gpio_dis1_pu1";
				nvidia,function = "rsvd0";
				nvidia,pull = <TEGRA_PIN_PULL_NONE>;
				nvidia,tristate = <TEGRA_PIN_DISABLE>;
				nvidia,enable-input = <TEGRA_PIN_DISABLE>;
			};

			gpio_dis2_pu2 {
				nvidia,pins = "gpio_dis2_pu2";
				nvidia,function = "rsvd0";
				nvidia,pull = <TEGRA_PIN_PULL_NONE>;
				nvidia,tristate = <TEGRA_PIN_DISABLE>;
				nvidia,enable-input = <TEGRA_PIN_ENABLE>;
			};

			gpio_dis3_pu3 {
				nvidia,pins = "gpio_dis3_pu3";
				nvidia,function = "rsvd0";
				nvidia,pull = <TEGRA_PIN_PULL_NONE>;
				nvidia,tristate = <TEGRA_PIN_DISABLE>;
				nvidia,enable-input = <TEGRA_PIN_ENABLE>;
			};

			gpio_dis4_pu4 {
				nvidia,pins = "gpio_dis4_pu4";
				nvidia,function = "rsvd0";
				nvidia,pull = <TEGRA_PIN_PULL_NONE>;
				nvidia,tristate = <TEGRA_PIN_DISABLE>;
				nvidia,enable-input = <TEGRA_PIN_ENABLE>;
			};

			gpio_dis5_pu5 {
				nvidia,pins = "gpio_dis5_pu5";
				nvidia,function = "rsvd0";
				nvidia,pull = <TEGRA_PIN_PULL_UP>;
				nvidia,tristate = <TEGRA_PIN_DISABLE>;
				nvidia,enable-input = <TEGRA_PIN_ENABLE>;
			};

			power_on_pff0 {
				nvidia,pins = "power_on_pff0";
				nvidia,function = "rsvd0";
				nvidia,pull = <TEGRA_PIN_PULL_NONE>;
				nvidia,tristate = <TEGRA_PIN_DISABLE>;
				nvidia,enable-input = <TEGRA_PIN_ENABLE>;
			};

			vcomp_alert_ps4 {
				nvidia,pins = "vcomp_alert_ps4";
				nvidia,function = "rsvd1";
				nvidia,pull = <TEGRA_PIN_PULL_NONE>;
				nvidia,tristate = <TEGRA_PIN_DISABLE>;
				nvidia,enable-input = <TEGRA_PIN_DISABLE>;
			};

			batt_oc_ps2 {
				nvidia,pins = "batt_oc_ps2";
				nvidia,function = "rsvd1";
				nvidia,pull = <TEGRA_PIN_PULL_UP>;
				nvidia,tristate = <TEGRA_PIN_DISABLE>;
				nvidia,enable-input = <TEGRA_PIN_ENABLE>;
			};

			uart2_rts_px2 {
				nvidia,pins = "uart2_rts_px2";
				nvidia,function = "rsvd1";
				nvidia,pull = <TEGRA_PIN_PULL_NONE>;
				nvidia,tristate = <TEGRA_PIN_DISABLE>;
				nvidia,enable-input = <TEGRA_PIN_DISABLE>;
			};

			uart2_cts_px3 {
				nvidia,pins = "uart2_cts_px3";
				nvidia,function = "rsvd1";
				nvidia,pull = <TEGRA_PIN_PULL_UP>;
				nvidia,tristate = <TEGRA_PIN_DISABLE>;
				nvidia,enable-input = <TEGRA_PIN_ENABLE>;
			};

			gpio_mdm1_py0 {
				nvidia,pins = "gpio_mdm1_py0";
				nvidia,function = "rsvd0";
				nvidia,pull = <TEGRA_PIN_PULL_UP>;
				nvidia,tristate = <TEGRA_PIN_DISABLE>;
				nvidia,enable-input = <TEGRA_PIN_ENABLE>;
			};

			gpio_mdm2_py1 {
				nvidia,pins = "gpio_mdm2_py1";
				nvidia,function = "rsvd0";
				nvidia,pull = <TEGRA_PIN_PULL_NONE>;
				nvidia,tristate = <TEGRA_PIN_DISABLE>;
				nvidia,enable-input = <TEGRA_PIN_ENABLE>;
			};

			gpio_mdm3_py2 {
				nvidia,pins = "gpio_mdm3_py2";
				nvidia,function = "rsvd0";
				nvidia,pull = <TEGRA_PIN_PULL_UP>;
				nvidia,tristate = <TEGRA_PIN_DISABLE>;
				nvidia,enable-input = <TEGRA_PIN_ENABLE>;
			};

			gpio_mdm6_py5 {
				nvidia,pins = "gpio_mdm6_py5";
				nvidia,function = "rsvd1";
				nvidia,pull = <TEGRA_PIN_PULL_NONE>;
				nvidia,tristate = <TEGRA_PIN_DISABLE>;
				nvidia,enable-input = <TEGRA_PIN_ENABLE>;
			};

			bcpu_pwr_req_ph4 {
				nvidia,pins = "bcpu_pwr_req_ph4";
				nvidia,function = "rsvd0";
				nvidia,pull = <TEGRA_PIN_PULL_NONE>;
				nvidia,tristate = <TEGRA_PIN_DISABLE>;
				nvidia,enable-input = <TEGRA_PIN_DISABLE>;
			};

			gpu_pwr_req_ph6 {
				nvidia,pins = "gpu_pwr_req_ph6";
				nvidia,function = "rsvd0";
				nvidia,pull = <TEGRA_PIN_PULL_NONE>;
				nvidia,tristate = <TEGRA_PIN_DISABLE>;
				nvidia,enable-input = <TEGRA_PIN_DISABLE>;
			};

			gpio_sen0_pv0 {
				nvidia,pins = "gpio_sen0_pv0";
				nvidia,function = "rsvd0";
				nvidia,pull = <TEGRA_PIN_PULL_UP>;
				nvidia,tristate = <TEGRA_PIN_DISABLE>;
				nvidia,enable-input = <TEGRA_PIN_ENABLE>;
			};

			gpio_sen5_pv5 {
				nvidia,pins = "gpio_sen5_pv5";
				nvidia,function = "rsvd0";
				nvidia,pull = <TEGRA_PIN_PULL_NONE>;
				nvidia,tristate = <TEGRA_PIN_DISABLE>;
				nvidia,enable-input = <TEGRA_PIN_DISABLE>;
			};

			gpio_sen7_pv7 {
				nvidia,pins = "gpio_sen7_pv7";
				nvidia,function = "rsvd0";
				nvidia,pull = <TEGRA_PIN_PULL_UP>;
				nvidia,tristate = <TEGRA_PIN_DISABLE>;
				nvidia,enable-input = <TEGRA_PIN_ENABLE>;
			};

			touch_clk_pee2 {
				nvidia,pins = "touch_clk_pee2";
				nvidia,function = "rsvd1";
				nvidia,pull = <TEGRA_PIN_PULL_UP>;
				nvidia,tristate = <TEGRA_PIN_DISABLE>;
				nvidia,enable-input = <TEGRA_PIN_ENABLE>;
			};

			can_gpio0_paa0 {
				nvidia,pins = "can_gpio0_paa0";
				nvidia,function = "rsvd0";
				nvidia,pull = <TEGRA_PIN_PULL_NONE>;
				nvidia,tristate = <TEGRA_PIN_DISABLE>;
				nvidia,enable-input = <TEGRA_PIN_ENABLE>;
			};

			can_gpio1_paa1 {
				nvidia,pins = "can_gpio1_paa1";
				nvidia,function = "rsvd0";
				nvidia,pull = <TEGRA_PIN_PULL_NONE>;
				nvidia,tristate = <TEGRA_PIN_DISABLE>;
				nvidia,enable-input = <TEGRA_PIN_DISABLE>;
			};

			can_gpio2_paa2 {
				nvidia,pins = "can_gpio2_paa2";
				nvidia,function = "rsvd1";
				nvidia,pull = <TEGRA_PIN_PULL_NONE>;
				nvidia,tristate = <TEGRA_PIN_DISABLE>;
				nvidia,enable-input = <TEGRA_PIN_DISABLE>;
			};

			can_gpio3_paa3 {
				nvidia,pins = "can_gpio3_paa3";
				nvidia,function = "rsvd0";
				nvidia,pull = <TEGRA_PIN_PULL_NONE>;
				nvidia,tristate = <TEGRA_PIN_DISABLE>;
				nvidia,enable-input = <TEGRA_PIN_ENABLE>;
			};

			can_gpio4_paa4 {
				nvidia,pins = "can_gpio4_paa4";
				nvidia,function = "rsvd0";
				nvidia,pull = <TEGRA_PIN_PULL_NONE>;
				nvidia,tristate = <TEGRA_PIN_DISABLE>;
				nvidia,enable-input = <TEGRA_PIN_ENABLE>;
			};

			can_gpio5_paa5 {
				nvidia,pins = "can_gpio5_paa5";
				nvidia,function = "rsvd0";
				nvidia,pull = <TEGRA_PIN_PULL_NONE>;
				nvidia,tristate = <TEGRA_PIN_DISABLE>;
				nvidia,enable-input = <TEGRA_PIN_ENABLE>;
			};

			can_gpio6_paa6 {
				nvidia,pins = "can_gpio6_paa6";
				nvidia,function = "rsvd0";
				nvidia,pull = <TEGRA_PIN_PULL_NONE>;
				nvidia,tristate = <TEGRA_PIN_DISABLE>;
				nvidia,enable-input = <TEGRA_PIN_ENABLE>;
			};

			can_gpio7_paa7 {
				nvidia,pins = "can_gpio7_paa7";
				nvidia,function = "rsvd0";
				nvidia,pull = <TEGRA_PIN_PULL_NONE>;
				nvidia,tristate = <TEGRA_PIN_DISABLE>;
				nvidia,enable-input = <TEGRA_PIN_DISABLE>;
			};

			gpio_edp0_pp3 {
				nvidia,pins = "gpio_edp0_pp3";
				nvidia,function = "rsvd0";
				nvidia,pull = <TEGRA_PIN_PULL_UP>;
				nvidia,tristate = <TEGRA_PIN_DISABLE>;
				nvidia,enable-input = <TEGRA_PIN_ENABLE>;
			};

			gpio_edp1_pp4 {
				nvidia,pins = "gpio_edp1_pp4";
				nvidia,function = "rsvd0";
				nvidia,pull = <TEGRA_PIN_PULL_UP>;
				nvidia,tristate = <TEGRA_PIN_DISABLE>;
				nvidia,enable-input = <TEGRA_PIN_ENABLE>;
			};

			gpio_edp2_pp5 {
				nvidia,pins = "gpio_edp2_pp5";
				nvidia,function = "rsvd0";
				nvidia,pull = <TEGRA_PIN_PULL_UP>;
				nvidia,tristate = <TEGRA_PIN_DISABLE>;
				nvidia,enable-input = <TEGRA_PIN_ENABLE>;
			};

			gpio_edp3_pp6 {
				nvidia,pins = "gpio_edp3_pp6";
				nvidia,function = "rsvd0";
				nvidia,pull = <TEGRA_PIN_PULL_UP>;
				nvidia,tristate = <TEGRA_PIN_DISABLE>;
				nvidia,enable-input = <TEGRA_PIN_ENABLE>;
			};
		};

		pinmux_unused_lowpower: unused_lowpower {
			gpio_sw3_pff3 {
				nvidia,pins = "gpio_sw3_pff3";
				nvidia,function = "rsvd0";
				nvidia,pull = <TEGRA_PIN_PULL_DOWN>;
				nvidia,tristate = <TEGRA_PIN_ENABLE>;
				nvidia,enable-input = <TEGRA_PIN_DISABLE>;
			};

			gpio_mdm5_py4 {
				nvidia,pins = "gpio_mdm5_py4";
				nvidia,function = "rsvd0";
				nvidia,pull = <TEGRA_PIN_PULL_DOWN>;
				nvidia,tristate = <TEGRA_PIN_ENABLE>;
				nvidia,enable-input = <TEGRA_PIN_DISABLE>;
			};

			gpio_mdm7_py6 {
				nvidia,pins = "gpio_mdm7_py6";
				nvidia,function = "rsvd0";
				nvidia,pull = <TEGRA_PIN_PULL_DOWN>;
				nvidia,tristate = <TEGRA_PIN_ENABLE>;
				nvidia,enable-input = <TEGRA_PIN_DISABLE>;
			};

			mcpu_pwr_req_ph5 {
				nvidia,pins = "mcpu_pwr_req_ph5";
				nvidia,function = "rsvd0";
				nvidia,pull = <TEGRA_PIN_PULL_DOWN>;
				nvidia,tristate = <TEGRA_PIN_ENABLE>;
				nvidia,enable-input = <TEGRA_PIN_DISABLE>;
			};

			gp_pwm7_pl7 {
				nvidia,pins = "gp_pwm7_pl7";
				nvidia,function = "rsvd1";
				nvidia,pull = <TEGRA_PIN_PULL_DOWN>;
				nvidia,tristate = <TEGRA_PIN_ENABLE>;
				nvidia,enable-input = <TEGRA_PIN_DISABLE>;
			};

			directdc1_clk_pq0 {
				nvidia,pins = "directdc1_clk_pq0";
				nvidia,function = "rsvd1";
				nvidia,pull = <TEGRA_PIN_PULL_DOWN>;
				nvidia,tristate = <TEGRA_PIN_ENABLE>;
				nvidia,enable-input = <TEGRA_PIN_DISABLE>;
			};

			directdc1_in_pq1 {
				nvidia,pins = "directdc1_in_pq1";
				nvidia,function = "rsvd1";
				nvidia,pull = <TEGRA_PIN_PULL_DOWN>;
				nvidia,tristate = <TEGRA_PIN_ENABLE>;
				nvidia,enable-input = <TEGRA_PIN_DISABLE>;
			};

			directdc1_out0_pq2 {
				nvidia,pins = "directdc1_out0_pq2";
				nvidia,function = "rsvd1";
				nvidia,pull = <TEGRA_PIN_PULL_DOWN>;
				nvidia,tristate = <TEGRA_PIN_ENABLE>;
				nvidia,enable-input = <TEGRA_PIN_DISABLE>;
			};

			directdc1_out1_pq3 {
				nvidia,pins = "directdc1_out1_pq3";
				nvidia,function = "rsvd1";
				nvidia,pull = <TEGRA_PIN_PULL_DOWN>;
				nvidia,tristate = <TEGRA_PIN_ENABLE>;
				nvidia,enable-input = <TEGRA_PIN_DISABLE>;
			};

			directdc1_out2_pq4 {
				nvidia,pins = "directdc1_out2_pq4";
				nvidia,function = "rsvd1";
				nvidia,pull = <TEGRA_PIN_PULL_DOWN>;
				nvidia,tristate = <TEGRA_PIN_ENABLE>;
				nvidia,enable-input = <TEGRA_PIN_DISABLE>;
			};

			directdc1_out3_pq5 {
				nvidia,pins = "directdc1_out3_pq5";
				nvidia,function = "rsvd1";
				nvidia,pull = <TEGRA_PIN_PULL_DOWN>;
				nvidia,tristate = <TEGRA_PIN_ENABLE>;
				nvidia,enable-input = <TEGRA_PIN_DISABLE>;
			};

			uart3_rts_pw4 {
				nvidia,pins = "uart3_rts_pw4";
				nvidia,function = "rsvd1";
				nvidia,pull = <TEGRA_PIN_PULL_DOWN>;
				nvidia,tristate = <TEGRA_PIN_ENABLE>;
				nvidia,enable-input = <TEGRA_PIN_DISABLE>;
			};

			uart3_cts_pw5 {
				nvidia,pins = "uart3_cts_pw5";
				nvidia,function = "rsvd1";
				nvidia,pull = <TEGRA_PIN_PULL_DOWN>;
				nvidia,tristate = <TEGRA_PIN_ENABLE>;
				nvidia,enable-input = <TEGRA_PIN_DISABLE>;
			};

			ufs0_ref_clk_pbb0 {
				nvidia,pins = "ufs0_ref_clk_pbb0";
				nvidia,function = "rsvd1";
				nvidia,pull = <TEGRA_PIN_PULL_DOWN>;
				nvidia,tristate = <TEGRA_PIN_ENABLE>;
				nvidia,enable-input = <TEGRA_PIN_DISABLE>;
			};

			ufs0_rst_pbb1 {
				nvidia,pins = "ufs0_rst_pbb1";
				nvidia,function = "rsvd1";
				nvidia,pull = <TEGRA_PIN_PULL_DOWN>;
				nvidia,tristate = <TEGRA_PIN_ENABLE>;
				nvidia,enable-input = <TEGRA_PIN_DISABLE>;
			};
		};

		drive_default: drive {
		};
	};
};

